# G32R501 register map
Vendor: Geehy Semiconductor Co., Ltd.; Series: G32R5; File version: 1.0
CPU: CM55 r0p1, little endian, MPU, FPU, double-precision FPU, DSP, VTOR, 4 interrupt priority bits
Registers are 32-bit, read-write, reset 0x0 unless marked. A register's access mark holds for its fields unless they carry their own. Offsets are from the block's base; [hi:lo] are bit positions; {n}, {i} and the like mark numbered series.

## I2CA — I2C
Base 0x50001400
0x00 I2COADDR 16-bit — I2C own address
  [9:0] OADDR
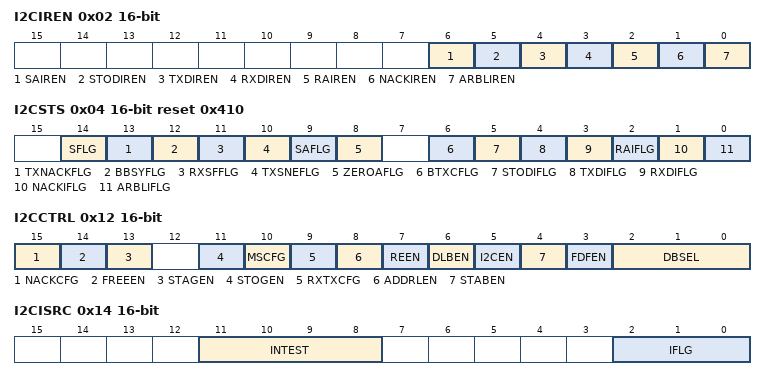
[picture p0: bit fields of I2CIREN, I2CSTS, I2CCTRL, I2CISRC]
0x02 I2CIREN 16-bit — I2C Interrupt Enable
  [6] SAIREN — slave Addressed interrupt request enable
  [5] STODIREN — Stop condition detected interrupt request enable
  [4] TXDIREN — Transmit data ready interrupt request enable
  [3] RXDIREN — Receive data ready interrupt request enable
  [2] RAIREN — Register access ready interrupt request enable
  [1] NACKIREN — No acknowledgment interrupt request enable
  [0] ARBLIREN — Arbitration lost interrupt request enable
0x04 I2CSTS 16-bit access per field reset 0x410 — I2C Status
  [14] SFLG rw-once — Slave Flag
  [13] TXNACKFLG rw-once — Transmit No acknowledgment flag
  [12] BBSYFLG ro — Bus busy Flag
  [11] RXSFFLG ro — Receive shift register full Flag
  [10] TXSNEFLG ro — Transmit shift register not empty Flag
  [9] SAFLG ro — slave Addressed Flag
  [8] ZEROAFLG ro — all zeros address flag
  [6] BTXCFLG rw-once — Byte Transmit Complete flag
  [5] STODIFLG rw-once — Stop condition detected interrupt flag
  [4] TXDIFLG ro — Transmit data ready interrupt flag
  [3] RXDIFLG rw-once — Receive data ready interrupt flag
  [2] RAIFLG rw-once — Register access ready interrupt flag
  [1] NACKIFLG rw-once — No acknowledgment interrupt flag
  [0] ARBLIFLG rw-once — Arbitration lost interrupt flag
0x06 I2CCLKL 16-bit — I2C Clock low-time divider
  [15:0] CLKL — Clock low-time divide value
0x08 I2CCLKH 16-bit — I2C Clock high-time divider
  [15:0] CLKH — Clock high-time divide value
0x0A I2CCNT 16-bit — I2C Data count
  [15:0] CNT — count value
0x0C I2CRXD 16-bit ro — I2C Data receive
  [7:0] RXD — Receive data
0x0E I2CSADDR 16-bit reset 0x3FF — I2C Slave address
  [9:0] SADDR — slave address Set
0x10 I2CTXD 16-bit — I2C Data Transmit
  [7:0] TXD — Transmit data
0x12 I2CCTRL 16-bit — I2C Mode
  [15] NACKCFG — NACK mode Configure
  [14] FREEEN — I2C Free Run Enable
  [13] STAGEN — start condition Generating
  [11] STOGEN — stop condition Generating
  [10] MSCFG — Master Slave mode configure
  [9] RXTXCFG — Receive Transmit mode Configure
  [8] ADDRLEN — Address Length Configure
  [7] REEN — Repeat mode enable
  [6] DLBEN — Digital loopback mode enable
  [5] I2CEN — I2C enable
  [4] STABEN — Start byte mode enable
  [3] FDFEN — Free data format mode enable
  [2:0] DBSEL — data byte select
0x14 I2CISRC 16-bit access per field — I2C Interrupt Source
  [11:8] INTEST rw — internal testing
  [2:0] IFLG ro — Interrupt Flag
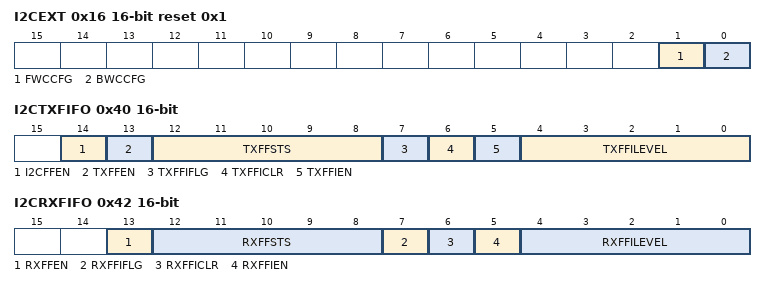
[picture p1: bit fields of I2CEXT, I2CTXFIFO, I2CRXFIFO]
0x16 I2CEXT 16-bit reset 0x1 — I2C Extended Mode
  [1] FWCCFG — Forward Compatibility mode Configure
  [0] BWCCFG — Backwards compatibility mode Configure
0x18 I2CPSC 16-bit — I2C Prescaler
  [7:0] PSC — prescaler value
0x40 I2CTXFIFO 16-bit access per field — I2C FIFO Transmit
  [14] I2CFFEN rw — I2C FIFO enable
  [13] TXFFEN rw — transmit FIFO enable
  [12:8] TXFFSTS ro — transmit FIFO status
  [7] TXFFIFLG ro — Transmit FIFO interrupt flag
  [6] TXFFICLR rw-once — Transmit FIFO Interrupt Flag Clear
  [5] TXFFIEN rw — Transmit FIFO Interrupt Enable
  [4:0] TXFFILEVEL rw — Transmit FIFO interrupt level Set
0x42 I2CRXFIFO 16-bit access per field — I2C FIFO Receive
  [13] RXFFEN rw — Receive FIFO enable
  [12:8] RXFFSTS ro — Receive FIFO status
  [7] RXFFIFLG ro — Receive FIFO interrupt flag
  [6] RXFFICLR rw-once — Receive FIFO Interrupt Flag Clear
  [5] RXFFIEN rw — Receive FIFO Interrupt Enable
  [4:0] RXFFILEVEL rw — Receive FIFO interrupt level Set

## EXTI
Base 0x50111000
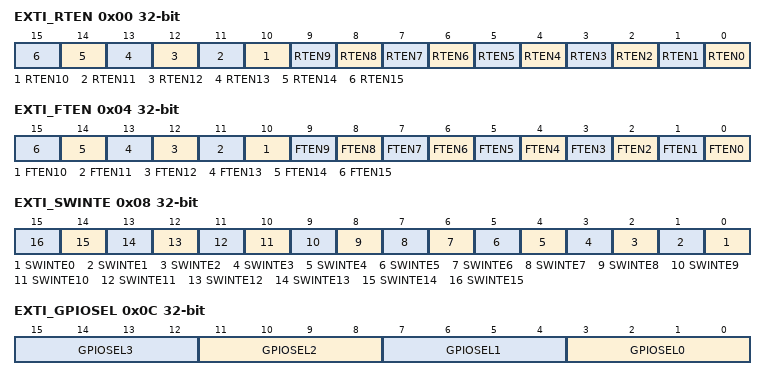
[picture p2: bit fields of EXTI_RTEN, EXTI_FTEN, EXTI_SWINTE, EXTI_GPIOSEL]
0x00 EXTI_RTEN — Rising Trigger Event Enable
  [n] RTEN{n} (n=0..15) — Rising Trigger Event Enable and Interrupt of Line {n}
0x04 EXTI_FTEN — Falling Trigger Event Enable
  [n] FTEN{n} (n=0..15) — Falling Trigger Event Enable and Interrupt of Line {n}
0x08 EXTI_SWINTE — Software Interrupt Event
  [n] SWINTE{n} (n=0..15) — Software Interrupt Event on Line {n}
0x0C EXTI_GPIOSEL — EINT_GPIO_SEL
  [4n+3:4n] GPIOSEL{n} (n=0..3) — GPIO Trigger signal select {n}
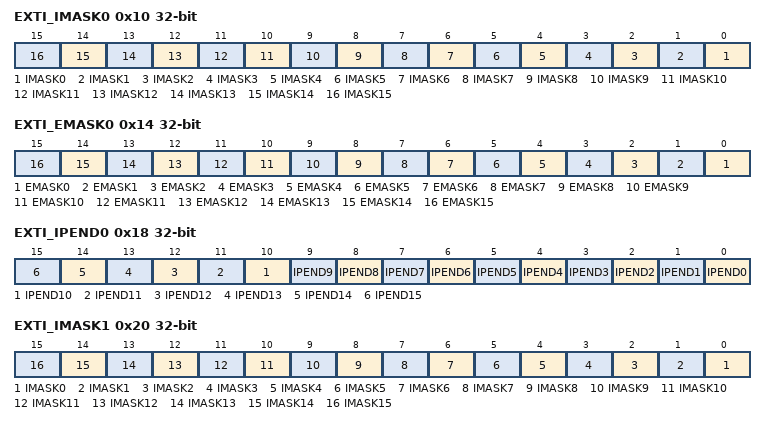
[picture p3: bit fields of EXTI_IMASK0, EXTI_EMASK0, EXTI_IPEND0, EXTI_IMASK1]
0x10 EXTI_IMASK0 — CPU0_EINT_IMASK
  [n] IMASK{n} (n=0..15) — Interrupt Request Mask on Line {n}
0x14 EXTI_EMASK0 — CPU0_EINT_EMASK
  [n] EMASK{n} (n=0..15) — Event Request Mask on Line {n}
0x18 EXTI_IPEND0 — CPU0_EINT_IPEND
  [n] IPEND{n} (n=0..15) — Interrupt Pending Occur of Line {n} Flag
0x20 EXTI_IMASK1 — CPU1_EINT_IMASK
  [n] IMASK{n} (n=0..15) — Interrupt Request Mask on Line {n}
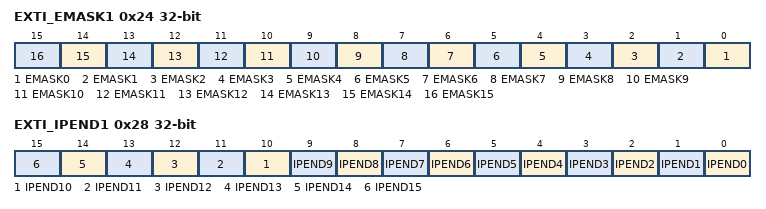
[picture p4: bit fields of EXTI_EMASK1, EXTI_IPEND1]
0x24 EXTI_EMASK1 — CPU1_EINT_EMASK
  [n] EMASK{n} (n=0..15) — Event Request Mask on Line {n}
0x28 EXTI_IPEND1 — CPU1_EINT_IPEND
  [n] IPEND{n} (n=0..15) — Interrupt Pending Occur of Line {n} Flag
{0x20+4i} EXTI_INT{i}CNT ro (i=4..6) — INT{i}_COUNTER
  [15:0] INT{i}_COUNTER
